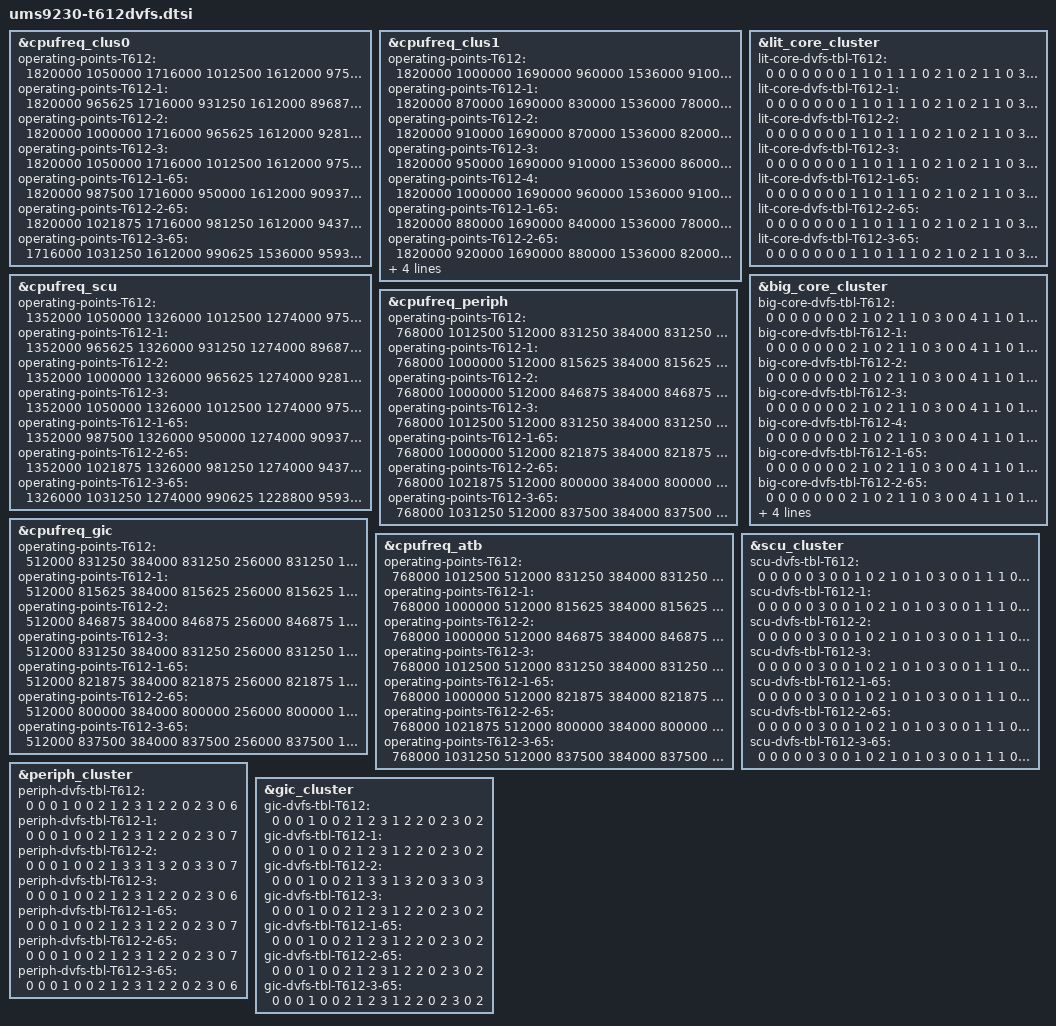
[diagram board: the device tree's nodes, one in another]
// SPDX-License-Identifier: (GPL-2.0+ OR MIT)
/*
 * Unisoc qogirl6 platform T612 SOC DVFS DTS file
 *
 * Copyright (C) 2021, Unisoc Communications Inc.
 */

#include "qogirl6.dtsi"
#include "ums9230.dtsi"

&cpufreq_clus0 {
	/* operating-points-T612-0-0
	 * T606/T612-soc_ver 0-binning 0-temp
	 */
	operating-points-T612 = <
		/* kHZ   uV */
		1820000 1050000
		1716000 1012500
		1612000 975000
		1536000 946875
		1378000 887500
		1228800 831250
		1040000 762500
		884000  700000
		768000  700000
		614400  700000
	>;

	operating-points-T612-1 = <
		/* kHZ   uV */
		1820000 965625
		1716000 931250
		1612000 896875
		1536000 868750
		1378000 815625
		1228800 762500
		1040000 700000
		884000  700000
		768000  700000
		614400  700000
	>;

	operating-points-T612-2 = <
		/* kHZ   uV */
		1820000 1000000
		1716000 965625
		1612000 928125
		1536000 900000
		1378000 846875
		1228800 793750
		1040000 725000
		884000  700000
		768000  700000
		614400  700000
	>;

	operating-points-T612-3 = <
		/* kHZ   uV */
		1820000 1050000
		1716000 1012500
		1612000 975000
		1536000 946875
		1378000 887500
		1228800 831250
		1040000 762500
		884000  700000
		768000  700000
		614400  700000
	>;

	operating-points-T612-1-65 = <
		/* kHZ   uV */
		1820000 987500
		1716000 950000
		1612000 909375
		1536000 881250
		1378000 821875
		1228800 768750
		1040000 700000
		884000  700000
		768000  700000
		614400  700000
	>;

	operating-points-T612-2-65 = <
		/* kHZ   uV */
		1820000 1021875
		1716000 981250
		1612000 943750
		1536000 915625
		1378000 856250
		1228800 800000
		1040000 728125
		884000  700000
		768000  700000
		614400  700000
	>;

	operating-points-T612-3-65 = <
		/* kHZ   uV */
		1716000 1031250
		1612000 990625
		1536000 959375
		1378000 896875
		1228800 837500
		1040000 765625
		884000  700000
		768000  700000
		614400  700000
	>;
};

&cpufreq_clus1 {
	operating-points-T612 = <
		/* kHZ   uV */
		1820000 1000000
		1690000 960000
		1536000 910000
		1404000 870000
		1228800 810000
		1040000 750000
		768000  750000
	>;

	operating-points-T612-1 = <
		/* kHZ   uV */
		1820000 870000
		1690000 830000
		1536000 780000
		1404000 750000
		1228800 750000
		1040000 750000
		768000  750000
	>;

	operating-points-T612-2 = <
		/* kHZ   uV */
		1820000 910000
		1690000 870000
		1536000 820000
		1404000 780000
		1228800 750000
		1040000 750000
		768000  750000
	>;

	operating-points-T612-3 = <
		/* kHZ   uV */
		1820000 950000
		1690000 910000
		1536000 860000
		1404000 820000
		1228800 760000
		1040000 750000
		768000  750000
	>;

	operating-points-T612-4 = <
		/* kHZ   uV */
		1820000 1000000
		1690000 960000
		1536000 910000
		1404000 870000
		1228800 810000
		1040000 750000
		768000  750000
	>;

	operating-points-T612-1-65 = <
		/* kHZ   uV */
		1820000 880000
		1690000 840000
		1536000 780000
		1404000 750000
		1228800 750000
		1040000 750000
		768000  750000
	>;

	operating-points-T612-2-65 = <
		/* kHZ   uV */
		1820000 920000
		1690000 880000
		1536000 820000
		1404000 780000
		1228800 750000
		1040000 750000
		768000  750000
	>;

	operating-points-T612-3-65 = <
		/* kHZ   uV */
		1820000 960000
		1690000 920000
		1536000 870000
		1404000 820000
		1228800 760000
		1040000 750000
		768000  750000
	>;

	operating-points-T612-4-65 = <
		/* kHZ   uV */
		1820000 1010000
		1690000 970000
		1536000 920000
		1404000 870000
		1228800 820000
		1040000 750000
		768000  750000
	>;
};

&cpufreq_scu {
	operating-points-T612 = <
		/* kHZ   uV */
		1352000 1050000
		1326000 1012500
		1274000 975000
		1228800 946875
		1092000 887500
		962000  831250
		768000  762500
		702000  700000
		614400  700000
		546000  700000
	>;

	operating-points-T612-1 = <
		/* kHZ   uV */
		1352000 965625
		1326000 931250
		1274000 896875
		1228800 868750
		1092000 815625
		962000  762500
		768000  700000
		702000  700000
		614400  700000
		546000  700000
	>;

	operating-points-T612-2 = <
		/* kHZ   uV */
		1352000 1000000
		1326000 965625
		1274000 928125
		1228800 900000
		1092000 846875
		962000  793750
		768000  725000
		702000  700000
		614400  700000
		546000  700000
	>;

	operating-points-T612-3 = <
		/* kHZ   uV */
		1352000 1050000
		1326000 1012500
		1274000 975000
		1228800 946875
		1092000 887500
		962000  831250
		768000  762500
		702000  700000
		614400  700000
		546000  700000
	>;

	operating-points-T612-1-65 = <
		/* kHZ   uV */
		1352000 987500
		1326000 950000
		1274000 909375
		1228800 881250
		1092000 821875
		962000  768750
		768000  700000
		702000  700000
		614400  700000
		546000  700000
	>;

	operating-points-T612-2-65 = <
		/* kHZ   uV */
		1352000 1021875
		1326000 981250
		1274000 943750
		1228800 915625
		1092000 856250
		962000  800000
		768000  728125
		702000  700000
		614400  700000
		546000  700000
	>;

	operating-points-T612-3-65 = <
		/* kHZ   uV */
		1326000 1031250
		1274000 990625
		1228800 959375
		1092000 896875
		962000  837500
		768000  765625
		702000  700000
		614400  700000
		546000  700000
	>;
};

&cpufreq_periph {
	operating-points-T612 = <
		/* kHZ   uV */
		768000  1012500
		512000  831250
		384000  831250
		256000  831250
		153600  700000
	>;

	operating-points-T612-1 = <
		/* kHZ   uV */
		768000  1000000
		512000  815625
		384000  815625
		256000  815625
		153600  700000
	>;

	operating-points-T612-2 = <
		/* kHZ   uV */
		768000  1000000
		512000  846875
		384000  846875
		256000  846875
		153600  700000
	>;

	operating-points-T612-3 = <
		/* kHZ   uV */
		768000  1012500
		512000  831250
		384000  831250
		256000  831250
		153600  700000
	>;

	operating-points-T612-1-65 = <
		/* kHZ   uV */
		768000  1000000
		512000  821875
		384000  821875
		256000  821875
		153600  700000
	>;

	operating-points-T612-2-65 = <
		/* kHZ   uV */
		768000  1021875
		512000  800000
		384000  800000
		256000  800000
		153600  700000
	>;

	operating-points-T612-3-65 = <
		/* kHZ   uV */
		768000  1031250
		512000  837500
		384000  837500
		256000  837500
		153600  700000
	>;
};

&cpufreq_gic {
	operating-points-T612 = <
		/* kHZ   uV */
		512000  831250
		384000  831250
		256000  831250
		192000  831250
		153600  700000
	>;

	operating-points-T612-1 = <
		/* kHZ   uV */
		512000  815625
		384000  815625
		256000  815625
		192000  815625
		153600  700000
	>;

	operating-points-T612-2 = <
		/* kHZ   uV */
		512000  846875
		384000  846875
		256000  846875
		192000  846875
		153600  700000
	>;

	operating-points-T612-3 = <
		/* kHZ   uV */
		512000  831250
		384000  831250
		256000  831250
		192000  831250
		153600  700000
	>;

	operating-points-T612-1-65 = <
		/* kHZ   uV */
		512000  821875
		384000  821875
		256000  821875
		192000  821875
		153600  700000
	>;

	operating-points-T612-2-65 = <
		/* kHZ   uV */
		512000  800000
		384000  800000
		256000  800000
		192000  800000
		153600  700000
	>;

	operating-points-T612-3-65 = <
		/* kHZ   uV */
		512000  837500
		384000  837500
		256000  837500
		192000  837500
		153600  700000
	>;
};

&cpufreq_atb {
	operating-points-T612 = <
		/* kHZ   uV */
		768000  1012500
		512000  831250
		384000  831250
		256000  700000
		153600  700000
	>;

	operating-points-T612-1 = <
		/* kHZ   uV */
		768000  1000000
		512000  815625
		384000  815625
		256000  700000
		153600  700000
	>;

	operating-points-T612-2 = <
		/* kHZ   uV */
		768000  1000000
		512000  846875
		384000  846875
		256000  700000
		153600  700000
	>;

	operating-points-T612-3 = <
		/* kHZ   uV */
		768000  1012500
		512000  831250
		384000  831250
		256000  700000
		153600  700000
	>;

	operating-points-T612-1-65 = <
		/* kHZ   uV */
		768000  1000000
		512000  821875
		384000  821875
		256000  700000
		153600  700000
	>;

	operating-points-T612-2-65 = <
		/* kHZ   uV */
		768000  1021875
		512000  800000
		384000  800000
		256000  700000
		153600  700000
	>;

	operating-points-T612-3-65 = <
		/* kHZ   uV */
		768000  1031250
		512000  837500
		384000  837500
		256000  700000
		153600  700000
	>;
};

&lit_core_cluster {
	/* lit-core-dvfs-tbl-T612-0-0
	 * T606/T612-soc_ver 0-binning 0-temp
	 * sel, div, vol, vote_scu, vote_peri, vote_gic, mpllx
	 */
	lit-core-dvfs-tbl-T612 = <
		0 0 0 0  0 0 0
		1 1 0 1  1 1 0
		2 1 0 2  1 1 0
		3 0 0 3  1 1 0
		3 0 1 4  1 1 1
		1 0 2 5  1 1 0
		3 0 3 6  4 4 2
		2 0 4 7  4 4 0
		3 0 5 8  4 5 3
		3 0 6 9  4 5 4
		3 0 7 10 4 5 5
	>;

	lit-core-dvfs-tbl-T612-1 = <
		0 0 0 0  0 0 0
		1 1 0 1  1 1 0
		2 1 0 2  1 1 0
		3 0 0 3  1 1 0
		3 0 0 4  1 1 1
		1 0 1 5  1 1 0
		3 0 2 6  4 4 2
		2 0 3 7  4 4 0
		3 0 4 8  4 5 3
		3 0 5 9  4 5 4
		3 0 6 10 4 5 5
	>;

	lit-core-dvfs-tbl-T612-2 = <
		0 0 0 0  0 0 0
		1 1 0 1  1 1 0
		2 1 0 2  1 1 0
		3 0 0 3  1 1 0
		3 0 1 4  1 1 1
		1 0 2 5  1 1 0
		3 0 3 6  4 4 2
		2 0 4 7  4 4 0
		3 0 5 8  4 5 3
		3 0 6 9  4 5 4
		3 0 7 10 4 5 5
	>;

	lit-core-dvfs-tbl-T612-3 = <
		0 0 0 0  0 0 0
		1 1 0 1  1 1 0
		2 1 0 2  1 1 0
		3 0 0 3  1 1 0
		3 0 1 4  1 1 1
		1 0 2 5  1 1 0
		3 0 3 6  4 4 2
		2 0 4 7  4 4 0
		3 0 5 8  4 5 3
		3 0 6 9  4 5 4
		3 0 7 10 4 5 5
	>;

	lit-core-dvfs-tbl-T612-1-65 = <
		0 0 0 0  0 0 0
		1 1 0 1  1 1 0
		2 1 0 2  1 1 0
		3 0 0 3  1 1 0
		3 0 0 4  1 1 1
		1 0 1 5  1 1 0
		3 0 2 6  4 4 2
		2 0 3 7  4 4 0
		3 0 4 8  4 5 3
		3 0 5 9  4 5 4
		3 0 6 10 4 5 5
	>;

	lit-core-dvfs-tbl-T612-2-65 = <
		0 0 0 0  0 0 0
		1 1 0 1  1 1 0
		2 1 0 2  1 1 0
		3 0 0 3  1 1 0
		3 0 1 4  1 1 1
		1 0 2 5  1 1 0
		3 0 3 6  4 4 2
		2 0 4 7  4 4 0
		3 0 5 8  4 5 3
		3 0 6 9  4 5 4
		3 0 7 10 4 5 5
	>;

	lit-core-dvfs-tbl-T612-3-65 = <
		0 0 0 0  0 0 0
		1 1 0 1  1 1 0
		2 1 0 2  1 1 0
		3 0 0 3  1 1 0
		3 0 1 4  1 1 1
		1 0 2 5  1 1 0
		3 0 3 6  4 4 2
		2 0 4 7  4 4 0
		3 0 5 8  4 5 3
		3 0 6 9  4 5 4
		3 0 6 9  4 5 4
	>;
};

&big_core_cluster {
	/* sel, div, vol, vote_scu, vote_peri, vote_gic, mpllx */
	big-core-dvfs-tbl-T612 = <
		0 0 0 0  0 0 0
		2 1 0 2  1 1 0
		3 0 0 4  1 1 0
		1 0 1 4  1 1 0
		3 0 2 6  4 4 1
		2 0 3 7  4 4 0
		3 0 4 8  4 5 3
		3 0 5 10 4 5 4
		3 0 5 10 4 5 4
		3 0 5 10 4 5 4
	>;

	big-core-dvfs-tbl-T612-1 = <
		0 0 0 0  0 0 0
		2 1 0 2  1 1 0
		3 0 0 4  1 1 0
		1 0 0 4  1 1 0
		3 0 0 6  4 4 1
		2 0 1 7  4 4 0
		3 0 2 8  4 5 3
		3 0 3 10 4 5 4
		3 0 3 10 4 5 4
		3 0 3 10 4 5 4
	>;

	big-core-dvfs-tbl-T612-2 = <
		0 0 0 0  0 0 0
		2 1 0 2  1 1 0
		3 0 0 4  1 1 0
		1 0 0 4  1 1 0
		3 0 1 6  4 4 1
		2 0 2 7  4 4 0
		3 0 3 8  4 5 3
		3 0 4 10 4 5 4
		3 0 4 10 4 5 4
		3 0 4 10 4 5 4
	>;

	big-core-dvfs-tbl-T612-3 = <
		0 0 0 0  0 0 0
		2 1 0 2  1 1 0
		3 0 0 4  1 1 0
		1 0 1 4  1 1 0
		3 0 2 6  4 4 1
		2 0 3 7  4 4 0
		3 0 4 8  4 5 3
		3 0 5 10 4 5 4
		3 0 5 10 4 5 4
		3 0 5 10 4 5 4
	>;

	big-core-dvfs-tbl-T612-4 = <
		0 0 0 0  0 0 0
		2 1 0 2  1 1 0
		3 0 0 4  1 1 0
		1 0 1 4  1 1 0
		3 0 2 6  4 4 1
		2 0 3 7  4 4 0
		3 0 4 8  4 5 3
		3 0 5 10 4 5 4
		3 0 5 10 4 5 4
		3 0 5 10 4 5 4
	>;

	big-core-dvfs-tbl-T612-1-65 = <
		0 0 0 0  0 0 0
		2 1 0 2  1 1 0
		3 0 0 4  1 1 0
		1 0 0 4  1 1 0
		3 0 0 6  4 4 1
		2 0 1 7  4 4 0
		3 0 2 8  4 5 3
		3 0 3 10 4 5 4
		3 0 3 10 4 5 4
		3 0 3 10 4 5 4
	>;

	big-core-dvfs-tbl-T612-2-65 = <
		0 0 0 0  0 0 0
		2 1 0 2  1 1 0
		3 0 0 4  1 1 0
		1 0 0 4  1 1 0
		3 0 1 6  4 4 1
		2 0 2 7  4 4 0
		3 0 3 8  4 5 3
		3 0 4 10 4 5 4
		3 0 4 10 4 5 4
		3 0 4 10 4 5 4
	>;

	big-core-dvfs-tbl-T612-3-65 = <
		0 0 0 0  0 0 0
		2 1 0 2  1 1 0
		3 0 0 4  1 1 0
		1 0 1 4  1 1 0
		3 0 2 6  4 4 1
		2 0 3 7  4 4 0
		3 0 4 8  4 5 3
		3 0 5 10 4 5 4
		3 0 5 10 4 5 4
		3 0 5 10 4 5 4
	>;

	big-core-dvfs-tbl-T612-4-65 = <
		0 0 0 0  0 0 0
		2 1 0 2  1 1 0
		3 0 0 4  1 1 0
		1 0 1 4  1 1 0
		3 0 2 6  4 4 1
		2 0 3 7  4 4 0
		3 0 4 8  4 5 3
		3 0 5 10 4 5 4
		3 0 5 10 4 5 4
		3 0 5 10 4 5 4
	>;
};

&scu_cluster {
	/* sel, div, vol, ace_div, mpllx */
	scu-dvfs-tbl-T612 = <
		0 0 0 0 0
		3 0 0 1 0
		2 1 0 1 0
		3 0 0 1 1
		1 0 1 1 0
		3 0 2 1 2
		3 0 3 1 3
		2 0 4 1 0
		3 0 5 1 4
		3 0 6 1 5
		3 0 7 1 6
	>;

	scu-dvfs-tbl-T612-1 = <
		0 0 0 0 0
		3 0 0 1 0
		2 1 0 1 0
		3 0 0 1 1
		1 0 0 1 0
		3 0 1 1 2
		3 0 2 1 3
		2 0 3 1 0
		3 0 4 1 4
		3 0 5 1 5
		3 0 6 1 6
	>;

	scu-dvfs-tbl-T612-2 = <
		0 0 0 0 0
		3 0 0 1 0
		2 1 0 1 0
		3 0 0 1 1
		1 0 1 1 0
		3 0 2 1 2
		3 0 3 1 3
		2 0 4 1 0
		3 0 5 1 4
		3 0 6 1 5
		3 0 7 1 6
	>;

	scu-dvfs-tbl-T612-3 = <
		0 0 0 0 0
		3 0 0 1 0
		2 1 0 1 0
		3 0 0 1 1
		1 0 1 1 0
		3 0 2 1 2
		3 0 3 1 3
		2 0 4 1 0
		3 0 5 1 4
		3 0 6 1 5
		3 0 7 1 6
	>;

	scu-dvfs-tbl-T612-1-65 = <
		0 0 0 0 0
		3 0 0 1 0
		2 1 0 1 0
		3 0 0 1 1
		1 0 0 1 0
		3 0 1 1 2
		3 0 2 1 3
		2 0 3 1 0
		3 0 4 1 4
		3 0 5 1 5
		3 0 6 1 6
	>;

	scu-dvfs-tbl-T612-2-65 = <
		0 0 0 0 0
		3 0 0 1 0
		2 1 0 1 0
		3 0 0 1 1
		1 0 1 1 0
		3 0 2 1 2
		3 0 3 1 3
		2 0 4 1 0
		3 0 5 1 4
		3 0 6 1 5
		3 0 7 1 6
	>;

	scu-dvfs-tbl-T612-3-65 = <
		0 0 0 0 0
		3 0 0 1 0
		2 1 0 1 0
		3 0 0 1 1
		1 0 1 1 0
		3 0 2 1 2
		3 0 3 1 3
		2 0 4 1 0
		3 0 5 1 4
		3 0 6 1 5
		3 0 6 1 5
	>;
};

&periph_cluster{
	/* sel, div, vol */
	periph-dvfs-tbl-T612 = <
		0 0 0
		1 0 0
		2 1 2
		3 1 2
		2 0 2
		3 0 6
	>;

	periph-dvfs-tbl-T612-1 = <
		0 0 0
		1 0 0
		2 1 2
		3 1 2
		2 0 2
		3 0 7
	>;

	periph-dvfs-tbl-T612-2 = <
		0 0 0
		1 0 0
		2 1 3
		3 1 3
		2 0 3
		3 0 7
	>;

	periph-dvfs-tbl-T612-3 = <
		0 0 0
		1 0 0
		2 1 2
		3 1 2
		2 0 2
		3 0 6
	>;

	periph-dvfs-tbl-T612-1-65 = <
		0 0 0
		1 0 0
		2 1 2
		3 1 2
		2 0 2
		3 0 7
	>;

	periph-dvfs-tbl-T612-2-65 = <
		0 0 0
		1 0 0
		2 1 2
		3 1 2
		2 0 2
		3 0 7
	>;

	periph-dvfs-tbl-T612-3-65 = <
		0 0 0
		1 0 0
		2 1 2
		3 1 2
		2 0 2
		3 0 6
	>;
};

&gic_cluster{
	/* sel, div, vol */
	gic-dvfs-tbl-T612 = <
		0 0 0
		1 0 0
		2 1 2
		3 1 2
		2 0 2
		3 0 2
	>;

	gic-dvfs-tbl-T612-1 = <
		0 0 0
		1 0 0
		2 1 2
		3 1 2
		2 0 2
		3 0 2
	>;

	gic-dvfs-tbl-T612-2 = <
		0 0 0
		1 0 0
		2 1 3
		3 1 3
		2 0 3
		3 0 3
	>;

	gic-dvfs-tbl-T612-3 = <
		0 0 0
		1 0 0
		2 1 2
		3 1 2
		2 0 2
		3 0 2
	>;

	gic-dvfs-tbl-T612-1-65 = <
		0 0 0
		1 0 0
		2 1 2
		3 1 2
		2 0 2
		3 0 2
	>;

	gic-dvfs-tbl-T612-2-65 = <
		0 0 0
		1 0 0
		2 1 2
		3 1 2
		2 0 2
		3 0 2
	>;

	gic-dvfs-tbl-T612-3-65 = <
		0 0 0
		1 0 0
		2 1 2
		3 1 2
		2 0 2
		3 0 2
	>;
};
